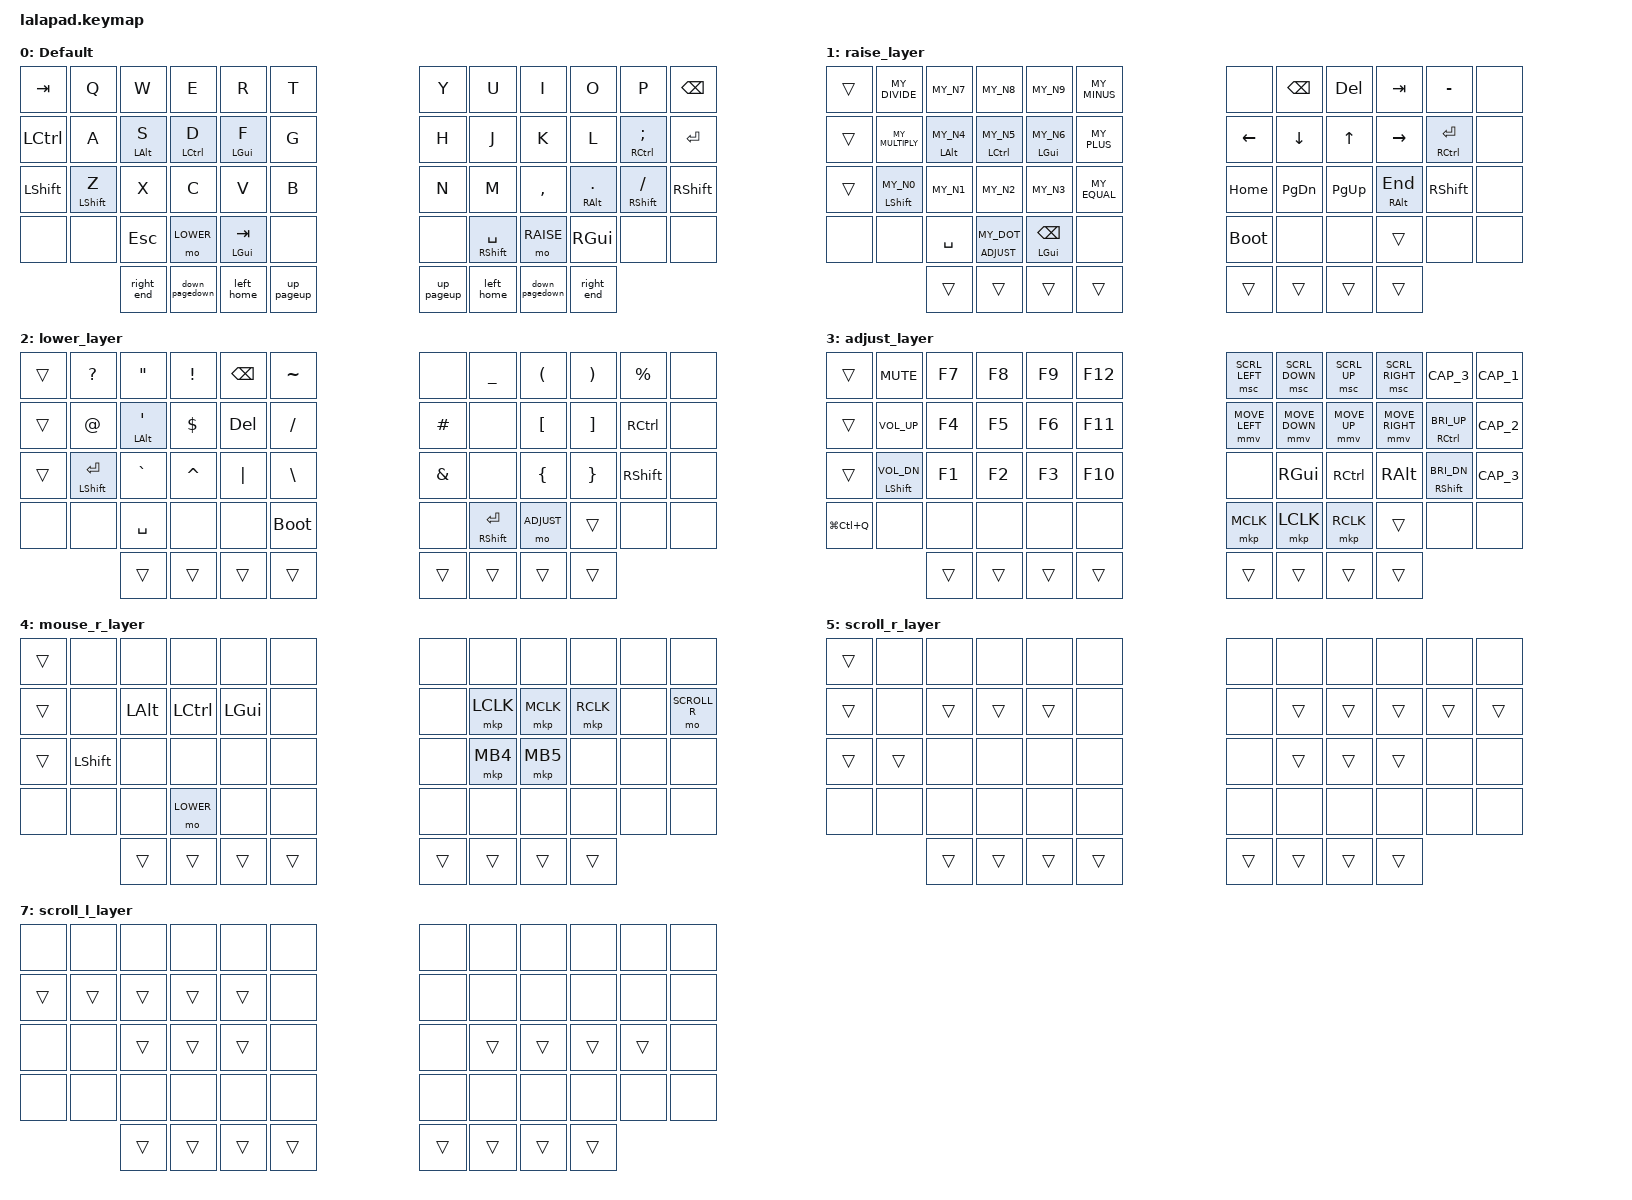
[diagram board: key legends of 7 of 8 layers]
#include <input/processors.dtsi>
#include <behaviors.dtsi>
#include <dt-bindings/zmk/bt.h>
#include <dt-bindings/zmk/keys.h>
#include <dt-bindings/zmk/outputs.h>

// Mouse Scroll Value
#define ZMK_POINTING_DEFAULT_SCRL_VAL 100
#include <dt-bindings/zmk/pointing.h>

#define DEFAULT   0
#define RAISE     1
#define LOWER     2
#define ADJUST    3
#define MOUSE_R   4
#define SCROLL_R  5
#define MOUSE_L   6
#define SCROLL_L  7

//╭───────┬───────┬───────┬───────┬───────┬───────╮                                   ╭───────┬───────┬───────┬───────┬───────┬───────╮
//|    0  |    1  |    2  |    3  |    4  |    5  |                                   |    6  |    7  |    8  |    9  |   10  |   11  |
//├───────┼───────┼───────┼───────┼───────┼───────┤                                   ├───────┼───────┼───────┼───────┼───────┼───────┤
//|   12  |   13  |   14  |   15  |   16  |   17  |                                   |   18  |   19  |   20  |   21  |   22  |   23  |
//├───────┼───────┼───────┼───────┼───────┼───────┤───────────────╮   ╭───────────────┼───────┼───────┼───────┼───────┼───────┼───────┤
//|   24  |   25  |   26  |   27  |   28  |   29  |               |   |               |   30  |   31  |   32  |   33  |   34  |   35  |
//├───────┼───────┼───────┼───────┴───────┼───────┼───────╮       |   |       ╭───────┼───────┼───────┴───────┼───────┼───────┼───────┤
//|   36  |   37  |   38  |               |   39  |   40  |   41  |   |   42  |   43  |   44  |               |   45  |   46  |   47  |
//╰───────┴───────┴───────╯               ╰───────┴───────╯ ──────╯   ╰────── ╰───────┴───────╯               ╰───────┴───────┴───────╯
//                | D-Pad LEFT                    |                                   | D-Pad RIGHT                   |
//                | RIGHT | DOWN  | LEFT  | UP    |                                   | UP    | LEFT  | DOWN  | RIGHT |
//                |   48  |   49  |   50  |   51  |                                   |   52  |   53  |   54  |   55  |

#define LEFT_TOP             0  1  2  3  4  5
#define RIGHT_TOP            6  7  8  9 10 11
#define LEFT_MID            12 13 14 15 16 17
#define RIGHT_MID           18 19 20 21 22 23
#define LEFT_BOTTOM         24 25 26 27 28 29
#define RIGHT_BOTTOM        30 31 32 33 34 35
#define LEFT_THUMBS         36 37 38 39 40
#define LEFT_BOTTOM_CENTER  41
#define RIGHT_BOTTOM_CENTER 42
#define RIGHT_THUMBS        43 44 45 46 47
#define LEFT_DPAD           48 49 50 51
#define RIGHT_DPAD          52 53 54 55

#define LEFT_KEYS  LEFT_TOP  LEFT_MID  LEFT_BOTTOM  LEFT_BOTTOM_CENTER
#define RIGHT_KEYS RIGHT_TOP RIGHT_MID RIGHT_BOTTOM RIGHT_BOTTOM_CENTER
#define THUMBS     LEFT_THUMBS RIGHT_THUMBS
#define DPAD       LEFT_DPAD   RIGHT_DPAD

#define MY_N0       KP_N0
#define MY_N1       KP_N1
#define MY_N2       KP_N2
#define MY_N3       KP_N3
#define MY_N4       KP_N4
#define MY_N5       KP_N5
#define MY_N6       KP_N6
#define MY_N7       KP_N7
#define MY_N8       KP_N8
#define MY_N9       KP_N9
#define MY_PLUS     KP_PLUS
#define MY_MINUS    KP_MINUS
#define MY_MULTIPLY KP_MULTIPLY
#define MY_DIVIDE   KP_DIVIDE
#define MY_EQUAL    KP_EQUAL
#define MY_DOT      KP_DOT

#define CAP_1       LG(LS(N3))
#define CAP_2       LG(LS(N4))
#define CAP_3       LG(LS(N5))
#define LOCK        &kp LG(LC(Q))

// cirque trackpad input&layer control
&glidepoint_listener_R {
    input-processors =
        <&zip_xy_transform (INPUT_TRANSFORM_XY_SWAP | INPUT_TRANSFORM_X_INVERT | INPUT_TRANSFORM_Y_INVERT)>,
        <&zip_xy_scaler 3 2>,
        <&zip_temp_layer MOUSE_R 500>;

    lowspeedmode {
        layers = <LOWER>;
        input-processors =
            <&zip_xy_transform (INPUT_TRANSFORM_XY_SWAP | INPUT_TRANSFORM_X_INVERT | INPUT_TRANSFORM_Y_INVERT)>,
            <&zip_xy_scaler 3 5>,
            <&zip_temp_layer MOUSE_R 500>;
    };

    scroller {
        layers = <SCROLL_R>;
        input-processors =
            <&zip_xy_to_scroll_mapper>,
            <&zip_scroll_transform (INPUT_TRANSFORM_XY_SWAP | INPUT_TRANSFORM_Y_INVERT)>,
            <&zip_scroll_scaler 1 8>;
    };
};
&glidepoint_listener_L {
    input-processors =
        <&zip_xy_transform (INPUT_TRANSFORM_XY_SWAP | INPUT_TRANSFORM_X_INVERT | INPUT_TRANSFORM_Y_INVERT)>,
        <&zip_xy_scaler 3 2>,
        <&zip_temp_layer MOUSE_L 500>;

    lowspeedmode {
        layers = <RAISE>;
        input-processors =
            <&zip_xy_transform (INPUT_TRANSFORM_XY_SWAP | INPUT_TRANSFORM_X_INVERT | INPUT_TRANSFORM_Y_INVERT)>,
            <&zip_xy_scaler 3 4>,
            <&zip_temp_layer MOUSE_L 500>;
    };

    scroller {
        layers = <SCROLL_L>;
        input-processors =
            <&zip_xy_to_scroll_mapper>,
            <&zip_scroll_transform (INPUT_TRANSFORM_XY_SWAP | INPUT_TRANSFORM_Y_INVERT)>,
            <&zip_scroll_scaler 1 6>;
    };
};

/ {

    behaviors {
        // for D-Pad
        up_pageup: up_pageup {
            compatible = "zmk,behavior-mod-morph";
            #binding-cells = <0>;
            bindings = <&kp UP>, <&kp PAGE_UP>;

            mods = <(MOD_LCTL|MOD_RCTL)>;
            label = "UP_PAGEUP";
        };
        down_pagedown: down_pagedown {
            compatible = "zmk,behavior-mod-morph";
            #binding-cells = <0>;
            bindings = <&kp DOWN>, <&kp PAGE_DOWN>;

            mods = <(MOD_LCTL|MOD_RCTL)>;
            label = "DOWN_PAGEDOWN";
        };
        left_home: left_home {
            compatible = "zmk,behavior-mod-morph";
            #binding-cells = <0>;
            bindings = <&kp LEFT>, <&kp HOME>;

            mods = <(MOD_LCTL|MOD_RCTL)>;
            label = "LEFT_HOME";
        };
        right_end: right_end {
            compatible = "zmk,behavior-mod-morph";
            #binding-cells = <0>;
            bindings = <&kp RIGHT>, <&kp END>;

            mods = <(MOD_LCTL|MOD_RCTL)>;
            label = "RIGHT_END";
        };

        mtb: mt_balanced {
            compatible = "zmk,behavior-hold-tap";
            #binding-cells = <2>;
            flavor = "balanced";
            tapping-term-ms = <200>;
            quick-tap-ms = <180>;
            bindings = <&kp>, <&kp>;
        };

        hml: home_row_mod_left {
            compatible = "zmk,behavior-hold-tap";
            #binding-cells = <2>;
            flavor = "balanced";
            require-prior-idle-ms = <150>;
            tapping-term-ms = <400>;
            quick-tap-ms = <180>;
            bindings = <&kp>, <&kp>;
            hold-trigger-key-positions = <DPAD THUMBS RIGHT_KEYS>;
            hold-trigger-on-release;
        };

        hmr: home_row_mod_right {
            compatible = "zmk,behavior-hold-tap";
            #binding-cells = <2>;
            flavor = "balanced";
            require-prior-idle-ms = <150>;
            tapping-term-ms = <400>;
            quick-tap-ms = <180>;
            bindings = <&kp>, <&kp>;
            hold-trigger-key-positions = <DPAD THUMBS LEFT_KEYS>;
            hold-trigger-on-release;
        };

        // for rotary encorder
        // default    : down/up scroll
        // w/shift    : left/right scroll
        // w/alt      : left/right. w/shift : selectable
        // w/alt+ctrl : down/up.    w/shift : selectable
        // w/ctrl     : switch tab
        // w/gui      : switch app
        enc_shift_ctrl_n: encorder_shift_ctrl_negative {
            compatible = "zmk,behavior-mod-morph";
            #binding-cells = <0>;
            bindings = <&msc SCRL_RIGHT>, <&kp LS(LC(TAB))>;

            mods = <(MOD_LCTL|MOD_RCTL)>;
        };

        enc_shift_ctrl_p: encorder_shift_ctrl_positive {
            compatible = "zmk,behavior-mod-morph";
            #binding-cells = <0>;
            bindings = <&msc SCRL_LEFT>, <&kp LC(TAB)>;

            mods = <(MOD_LCTL|MOD_RCTL)>;
        };

        enc_alt_ctrl_n: encorder_alt_ctrl_negative {
            compatible = "zmk,behavior-mod-morph";
            #binding-cells = <0>;
            bindings = <&kp LEFT>, <&kp UP>;

            mods = <(MOD_LCTL|MOD_RCTL)>;
        };

        enc_alt_ctrl_p: encorder_alt_ctrl_positive {
            compatible = "zmk,behavior-mod-morph";
            #binding-cells = <0>;
            bindings = <&kp RIGHT>, <&kp DOWN>;

            mods = <(MOD_LCTL|MOD_RCTL)>;
        };

        enc_shift_alt_ctrl_n: encorder_shift_alt_ctrl_negative {
            compatible = "zmk,behavior-mod-morph";
            #binding-cells = <0>;
            bindings = <&enc_shift_ctrl_n>, <&enc_alt_ctrl_n>;

            mods = <(MOD_LALT|MOD_RALT)>;
        };

        enc_shift_alt_ctrl_p: encorder_shift_alt_ctrl_positive {
            compatible = "zmk,behavior-mod-morph";
            #binding-cells = <0>;
            bindings = <&enc_shift_ctrl_p>, <&enc_alt_ctrl_p>;

            mods = <(MOD_LALT|MOD_RALT)>;
        };

        enc_all_modifiers_n: encorder_all_modifiers_negative {
            compatible = "zmk,behavior-mod-morph";
            #binding-cells = <0>;
            bindings = <&enc_shift_alt_ctrl_n>, <&kp LS(LG(TAB))>;

            mods = <(MOD_LGUI|MOD_RGUI)>;
            keep-mods = <(MOD_LGUI|MOD_RGUI)>;
        };

        enc_all_modifiers_p: encorder_all_modifiers_positive {
            compatible = "zmk,behavior-mod-morph";
            #binding-cells = <0>;
            bindings = <&enc_shift_alt_ctrl_p>, <&kp LG(TAB)>;

            mods = <(MOD_LGUI|MOD_RGUI)>;
            keep-mods = <(MOD_LGUI|MOD_RGUI)>;
        };

        enc_negative: encorder_nagative {
            compatible = "zmk,behavior-mod-morph";
            #binding-cells = <0>;
            bindings = <&msc SCRL_DOWN>, <&enc_all_modifiers_n>;

            mods = <(MOD_LSFT|MOD_RSFT|MOD_LALT|MOD_RALT|MOD_LCTL|MOD_RCTL|MOD_LGUI|MOD_RGUI)>;
        };

        enc_positive: encorder_positive {
            compatible = "zmk,behavior-mod-morph";
            #binding-cells = <0>;
            bindings = <&msc SCRL_UP>, <&enc_all_modifiers_p>;

            mods = <(MOD_LSFT|MOD_RSFT|MOD_LALT|MOD_RALT|MOD_LCTL|MOD_RCTL|MOD_LGUI|MOD_RGUI)>;
        };

        enc_root: encorder_root {
            compatible = "zmk,behavior-sensor-rotate";
            #sensor-binding-cells = <0>;
            bindings = <&enc_negative>, <&enc_positive>;

            tap-ms = <20>;
        };

        enc_var: encorder_variable {
            compatible = "zmk,behavior-sensor-rotate-var";
            #sensor-binding-cells = <2>;
            bindings = <&kp>, <&kp>;
        };
    };

    combo {
        compatible = "zmk,combos";
        // left and right shift for 40% keyboard layout
        combo_capsword_40 {
            timeout-ms = <50>;
            key-positions = <24 35>;
            bindings = <&caps_word>;
        };

        // left and right shift for 30% keyboard layout
        combo_capsword_30 {
            timeout-ms = <50>;
            key-positions = <25 34>;
            bindings = <&caps_word>;
        };

        // left thumbs
        combo_esc {
            timeout-ms = <50>;
            key-positions = <39 40>;
            bindings = <&kp ESC>;
        };

        // right thumbs
        combo_rgui {
            timeout-ms = <50>;
            key-positions = <43 44>;
            bindings = <&kp RGUI>;
        };
    };

    keymap {
        compatible = "zmk,keymap";

        DEFAULT {
            display-name = "Default";
            sensor-bindings = <&enc_root>,<&enc_root>;
            bindings = <
//╭────────────┬────────────┬────────────┬────────────┬────────────┬────────────╮                                                                    ╭────────────┬────────────┬────────────┬────────────┬──────────────┬──────────────╮
//|            |  Q         |  W         |  E         |  R         |  T         |                                                                    |  Y         |  U         |  I         | O          |  P           |              |
  &kp TAB      &kp Q        &kp W        &kp E        &kp R        &kp T                                                                             &kp Y        &kp U        &kp I        &kp O        &kp P          &kp BSPC
//├────────────┼────────────┼────────────┼────────────┼────────────┼────────────┤                                                                    ├────────────┼────────────┼────────────┼────────────┼──────────────┼──────────────┤
//|            |  A         |  S         |  D         |  F         |  G         |                                                                    |  H         |  J         |  K         | L          |  ;           |              |
  &kp LCTRL    &kp A        &hml LALT S  &hml LCTRL D &hml LGUI F  &kp G                                                                             &kp H        &kp J        &kp K        &kp L        &mt RCTRL SEMI &kp RET
//├────────────┼────────────┼────────────┼────────────┼────────────┼────────────┤────────────────────────╮                ╭──────────────────────────┼────────────┼────────────┼────────────┼────────────┼──────────────┼──────────────┤
//|            |  Z         |  X         |  C         |  V         |  B         |                        |                |                          |  N         |  M         |  ,         | .          |  /           |              |
  &kp LSHFT    &mtb LSHFT Z &kp X        &kp C        &kp V        &kp B                                                                             &kp N        &kp M        &kp COMMA    &mtb RALT DOT &mtb RSHFT FSLH &kp RSHFT
//├────────────┼────────────┼────────────┼────────────┴────────────┼────────────┼────────────╮           |                |             ╭────────────┼────────────┼────────────┴────────────┼────────────┼──────────────┼──────────────┤
  &none        &none        &kp ESC                                &mo LOWER    &mt LGUI TAB &none                        &none         &mtb RSHFT SPACE &mo RAISE                          &kp RGUI     &none          &none
//╰────────────┴────────────┴────────────╯                         ╰────────────┴────────────╯ ──────────╯                ╰──────────── ╰────────────┴────────────╯                         ╰────────────┴──────────────┴──────────────╯
//                          | D-Pad LEFT                                        |                                                                    | D-Pad RIGHT                                       |
//                          | RIGHT     | DOWN        | LEFT       | UP         |                                                                    | UP         | LEFT       | DOWN       | RIGHT      |
                            &right_end  &down_pagedown &left_home  &up_pageup                                                                        &up_pageup   &left_home   &down_pagedown &right_end
            >;
        };

        RAISE {
            display-name = "raise_layer";
            sensor-bindings = <&enc_var LG(MINUS) LG(PLUS)>,<&enc_var LG(MINUS) LG(PLUS)>;
            bindings = <
//╭────────────┬────────────┬────────────┬────────────┬────────────┬────────────╮                                                                    ╭────────────┬────────────┬────────────┬────────────┬──────────────┬──────────────╮
//|            |  /         |  7         |  8         |  9         |  -         |                                                                    |            |            |            |            |  -           |              |
  &trans       &kp MY_DIVIDE &kp MY_N7   &kp MY_N8    &kp MY_N9    &kp MY_MINUS                                                                      &none        &kp BSPC     &kp DEL      &kp TAB      &kp MINUS      &none
//├────────────┼────────────┼────────────┼────────────┼────────────┼────────────┤                                                                    ├────────────┼────────────┼────────────┼────────────┼──────────────┼──────────────┤
//|            |  *         |  4         |  5         |  6         |  +         |                                                                    |            |            |            |            |              |              |
  &trans &kp MY_MULTIPLY &hml LALT MY_N4 &hml LCTRL MY_N5 &hml LGUI MY_N6 &kp MY_PLUS                                                                &kp LEFT     &kp DOWN     &kp UP       &kp RIGHT    &mt RCTRL RET  &none
//├────────────┼────────────┼────────────┼────────────┼────────────┼────────────┤────────────────────────╮                ╭──────────────────────────┼────────────┼────────────┼────────────┼────────────┼──────────────┼──────────────┤
//|            |  0         |  1         |  2         |  3         |  =         |                        |                |                          |            |            |            |            |              |              |
  &trans     &mtb LSHFT MY_N0  &kp MY_N1 &kp MY_N2    &kp MY_N3    &kp MY_EQUAL                                                                      &kp HOME     &kp PG_DN    &kp PG_UP    &mtb RALT END &kp RSHFT     &none
//├────────────┼────────────┼────────────┼────────────┴────────────┼────────────┼────────────╮           |                |             ╭────────────┼────────────┼────────────┴────────────┼────────────┼──────────────┼──────────────┤
  &none        &none        &kp SPACE                           &lt ADJUST MY_DOT &mt LGUI BSPC &none                     &bootloader   &none        &none                                  &trans       &none          &none 
//╰────────────┴────────────┴────────────╯                         ╰────────────┴────────────╯ ──────────╯                ╰──────────── ╰────────────┴────────────╯                         ╰────────────┴──────────────┴──────────────╯
//                          | D-Pad LEFT                                        |                                                                    | D-Pad RIGHT                                       |
//                          | RIGHT     | DOWN        | LEFT       | UP         |                                                                    | UP         | LEFT       | DOWN       | RIGHT      |
                            &trans      &trans        &trans       &trans                                                                            &trans       &trans       &trans       &trans
            >;
        };

        LOWER {
            display-name = "lower_layer";
            sensor-bindings = <&enc_var C_BRI_DN C_BRI_UP>,<&enc_var C_BRI_DN C_BRI_UP>;
            bindings = <
//╭────────────┬────────────┬────────────┬────────────┬────────────┬────────────╮                                                                    ╭────────────┬────────────┬────────────┬────────────┬──────────────┬──────────────╮
//|            |  ?         |  "         |  !         |            |  ~         |                                                                    |            |  _         |  (         |  )         |  %           |              |
  &trans       &kp QMARK    &kp DQT      &kp EXCL     &kp BSPC     &kp TILDE                                                                         &none        &kp UNDER    &kp LPAR     &kp RPAR     &kp PRCNT      &none 
//├────────────┼────────────┼────────────┼────────────┼────────────┼────────────┤                                                                    ├────────────┼────────────┼────────────┼────────────┼──────────────┼──────────────┤
//|            |  @         |  '         |  $         |            |  /         |                                                                    |  #         |            |  [         |  ]         |              |              |
  &trans       &kp AT      &hml LALT SQT &kp DLLR     &kp DEL      &kp FSLH                                                                          &kp HASH     &none        &kp LBKT     &kp RBKT     &kp RCTRL      &none 
//├────────────┼────────────┼────────────┼────────────┼────────────┼────────────┤────────────────────────╮                ╭──────────────────────────┼────────────┼────────────┼────────────┼────────────┼──────────────┼──────────────┤
//|            |            |  `         |  ^         |  |         |  \         |                        |                |                          |  &         |            |  {         |  }         |              |              |
  &trans     &mtb LSHFT RET &kp GRAVE    &kp CARET    &kp PIPE     &kp BSLH                                                                          &kp AMPS     &none        &kp LBRC     &kp RBRC     &kp RSHFT      &none 
//├────────────┼────────────┼────────────┼────────────┴────────────┼────────────┼────────────╮           |                |             ╭────────────┼────────────┼────────────┴────────────┼────────────┼──────────────┼──────────────┤
  &none        &none        &kp SPACE                              &none        &none        &bootloader                  &none         &mtb RSHFT RET &mo ADJUST                           &trans       &none          &none 
//╰────────────┴────────────┴────────────╯                         ╰────────────┴────────────╯ ──────────╯                ╰──────────── ╰────────────┴────────────╯                         ╰────────────┴──────────────┴──────────────╯
//                          | D-Pad LEFT                                        |                                                                    | D-Pad RIGHT                                       |
//                          | RIGHT     | DOWN        | LEFT       | UP         |                                                                    | UP         | LEFT       | DOWN       | RIGHT      |
                            &trans      &trans        &trans       &trans                                                                            &trans       &trans       &trans       &trans
            >;
        };

        ADJUST {
            display-name = "adjust_layer";
            sensor-bindings = <&enc_var C_VOL_DN C_VOL_UP>,<&enc_var C_VOL_DN C_VOL_UP>;
            bindings = <
//╭────────────┬────────────┬────────────┬────────────┬────────────┬────────────╮                                                                    ╭────────────┬────────────┬────────────┬────────────┬──────────────┬──────────────╮
  &trans       &kp C_MUTE   &kp F7       &kp F8       &kp F9       &kp F12                                                                        &msc SCRL_LEFT &msc SCRL_DOWN &msc SCRL_UP &msc SCRL_RIGHT &kp CAP_3    &kp CAP_1
//├────────────┼────────────┼────────────┼────────────┼────────────┼────────────┤                                                                    ├────────────┼────────────┼────────────┼────────────┼──────────────┼──────────────┤
  &trans       &kp C_VOL_UP &kp F4       &kp F5       &kp F6       &kp F11                                                                        &mmv MOVE_LEFT &mmv MOVE_DOWN &mmv MOVE_UP &mmv MOVE_RIGHT &mt RCTL C_BRI_UP &kp CAP_2
//├────────────┼────────────┼────────────┼────────────┼────────────┼────────────┤────────────────────────╮                ╭──────────────────────────┼────────────┼────────────┼────────────┼────────────┼──────────────┼──────────────┤
  &trans &mt LSHFT C_VOL_DN &kp F1       &kp F2       &kp F3       &kp F10                                                                           &none        &kp RGUI     &kp RCTRL    &kp RALT  &mtb RSHFT C_BRI_DN &kp CAP_3
//├────────────┼────────────┼────────────┼────────────┴────────────┼────────────┼────────────╮           |                |             ╭────────────┼────────────┼────────────┴────────────┼────────────┼──────────────┼──────────────┤
  LOCK         &none        &none                                  &none        &none        &none                        &mkp MCLK     &mkp LCLK     &mkp RCLK                             &trans       &none          &none 
//╰────────────┴────────────┴────────────╯                         ╰────────────┴────────────╯ ──────────╯                ╰──────────── ╰────────────┴────────────╯                         ╰────────────┴──────────────┴──────────────╯
//                          | D-Pad LEFT                                        |                                                                    | D-Pad RIGHT                                       |
//                          | RIGHT     | DOWN        | LEFT       | UP         |                                                                    | UP         | LEFT       | DOWN       | RIGHT      |
                            &trans      &trans        &trans       &trans                                                                            &trans       &trans       &trans       &trans
            >;
        };

        MOUSE_R {
            display-name = "mouse_r_layer";
            bindings = <
//╭────────────┬────────────┬────────────┬────────────┬────────────┬────────────╮                                                                    ╭────────────┬────────────┬────────────┬────────────┬──────────────┬──────────────╮
  &trans       &none        &none        &none        &none        &none                                                                             &none        &none        &none        &none        &none          &none 
//├────────────┼────────────┼────────────┼────────────┼────────────┼────────────┤                                                                    ├────────────┼────────────┼────────────┼────────────┼──────────────┼──────────────┤
  &trans       &none        &kp LALT     &kp LCTRL    &kp LGUI     &none                                                                             &none        &mkp LCLK    &mkp MCLK    &mkp RCLK    &none          &mo SCROLL_R
//├────────────┼────────────┼────────────┼────────────┼────────────┼────────────┤────────────────────────╮                ╭──────────────────────────┼────────────┼────────────┼────────────┼────────────┼──────────────┼──────────────┤
  &trans       &kp LSHFT    &none        &none        &none        &none                                                                             &none        &mkp MB4     &mkp MB5     &none        &none          &none 
//├────────────┼────────────┼────────────┼────────────┴────────────┼────────────┼────────────╮           |                |             ╭────────────┼────────────┼────────────┴────────────┼────────────┼──────────────┼──────────────┤
  &none        &none        &none                                  &mo LOWER    &none        &none                        &none         &none        &none                                  &none        &none          &none 
//╰────────────┴────────────┴────────────╯                         ╰────────────┴────────────╯ ──────────╯                ╰──────────── ╰────────────┴────────────╯                         ╰────────────┴──────────────┴──────────────╯
//                          | D-Pad LEFT                                        |                                                                    | D-Pad RIGHT                                       |
//                          | RIGHT     | DOWN        | LEFT       | UP         |                                                                    | UP         | LEFT       | DOWN       | RIGHT      |
                            &trans      &trans        &trans       &trans                                                                            &trans       &trans       &trans       &trans
            >;
        };

        SCROLL_R {
            display-name = "scroll_r_layer";
            bindings = <
//╭────────────┬────────────┬────────────┬────────────┬────────────┬────────────╮                                                                    ╭────────────┬────────────┬────────────┬────────────┬──────────────┬──────────────╮
  &trans       &none        &none        &none        &none        &none                                                                             &none        &none        &none        &none        &none          &none 
//├────────────┼────────────┼────────────┼────────────┼────────────┼────────────┤                                                                    ├────────────┼────────────┼────────────┼────────────┼──────────────┼──────────────┤
  &trans       &none        &trans       &trans       &trans       &none                                                                             &none        &trans       &trans       &trans       &trans         &trans
//├────────────┼────────────┼────────────┼────────────┼────────────┼────────────┤────────────────────────╮                ╭──────────────────────────┼────────────┼────────────┼────────────┼────────────┼──────────────┼──────────────┤
  &trans       &trans       &none        &none        &none        &none                                                                             &none        &trans       &trans       &trans       &none          &none 
//├────────────┼────────────┼────────────┼────────────┴────────────┼────────────┼────────────╮           |                |             ╭────────────┼────────────┼────────────┴────────────┼────────────┼──────────────┼──────────────┤
  &none        &none        &none                                  &none        &none        &none                        &none         &none        &none                                  &none        &none          &none 
//╰────────────┴────────────┴────────────╯                         ╰────────────┴────────────╯ ──────────╯                ╰──────────── ╰────────────┴────────────╯                         ╰────────────┴──────────────┴──────────────╯
//                          | D-Pad LEFT                                        |                                                                    | D-Pad RIGHT                                       |
//                          | RIGHT     | DOWN        | LEFT       | UP         |                                                                    | UP         | LEFT       | DOWN       | RIGHT      |
                            &trans      &trans        &trans       &trans                                                                            &trans       &trans       &trans       &trans
            >;
        };

        MOUSE_L {
            display-name = "mouse_l_layer";
            bindings = <
//╭────────────┬────────────┬────────────┬────────────┬────────────┬────────────╮                                                                    ╭────────────┬────────────┬────────────┬────────────┬──────────────┬──────────────╮
  &none        &none        &none        &none        &none        &none                                                                             &none        &none        &none        &none        &none          &none 
//├────────────┼────────────┼────────────┼────────────┼────────────┼────────────┤                                                                    ├────────────┼────────────┼────────────┼────────────┼──────────────┼──────────────┤
  &mo SCROLL_L &none        &mkp RCLK    &mkp MCLK    &mkp LCLK    &none                                                                             &none        &none        &none        &none        &none          &none 
//├────────────┼────────────┼────────────┼────────────┼────────────┼────────────┤────────────────────────╮                ╭──────────────────────────┼────────────┼────────────┼────────────┼────────────┼──────────────┼──────────────┤
  &none        &none        &none        &mkp MB5     &mkp MB4     &none        &none                                                                &none        &kp LGUI     &kp LCTRL    &kp LALT     &kp LSHFT      &none    
//├────────────┼────────────┼────────────┼────────────┴────────────┼────────────┼────────────╮           |                |             ╭────────────┼────────────┼────────────┴────────────┼────────────┼──────────────┼──────────────┤
  &none        &none        &none                                  &none        &none        &none                        &none         &none        &mo RAISE                              &none        &none          &none 
//╰────────────┴────────────┴────────────╯                         ╰────────────┴────────────╯ ──────────╯                ╰──────────── ╰────────────┴────────────╯                         ╰────────────┴──────────────┴──────────────╯
//                          | D-Pad LEFT                                        |                                                                    | D-Pad RIGHT                                       |
//                          | RIGHT     | DOWN        | LEFT       | UP         |                                                                    | UP         | LEFT       | DOWN       | RIGHT      |
                            &trans      &trans        &trans       &trans                                                                            &trans       &trans       &trans       &trans
            >;
        };

        SCROLL_L {
            display-name = "scroll_l_layer";
            bindings = <
//╭────────────┬────────────┬────────────┬────────────┬────────────┬────────────╮                                                                    ╭────────────┬────────────┬────────────┬────────────┬──────────────┬──────────────╮
  &none        &none        &none        &none        &none        &none                                                                             &none        &none        &none        &none        &none          &none 
//├────────────┼────────────┼────────────┼────────────┼────────────┼────────────┤                                                                    ├────────────┼────────────┼────────────┼────────────┼──────────────┼──────────────┤
  &trans       &trans       &trans       &trans       &trans       &none                                                                             &none        &none        &none        &none        &none          &none 
//├────────────┼────────────┼────────────┼────────────┼────────────┼────────────┤────────────────────────╮                ╭──────────────────────────┼────────────┼────────────┼────────────┼────────────┼──────────────┼──────────────┤
  &none        &none        &trans       &trans       &trans       &none                                                                             &none        &trans       &trans       &trans       &trans         &none 
//├────────────┼────────────┼────────────┼────────────┴────────────┼────────────┼────────────╮           |                |             ╭────────────┼────────────┼────────────┴────────────┼────────────┼──────────────┼──────────────┤
  &none        &none        &none                                  &none        &none        &none                        &none         &none        &none                                  &none        &none          &none 
//╰────────────┴────────────┴────────────╯                         ╰────────────┴────────────╯ ──────────╯                ╰──────────── ╰────────────┴────────────╯                         ╰────────────┴──────────────┴──────────────╯
//                          | D-Pad LEFT                                        |                                                                    | D-Pad RIGHT                                       |
//                          | RIGHT     | DOWN        | LEFT       | UP         |                                                                    | UP         | LEFT       | DOWN       | RIGHT      |
                            &trans      &trans        &trans       &trans                                                                            &trans       &trans       &trans       &trans
            >;
        };
    };
};
